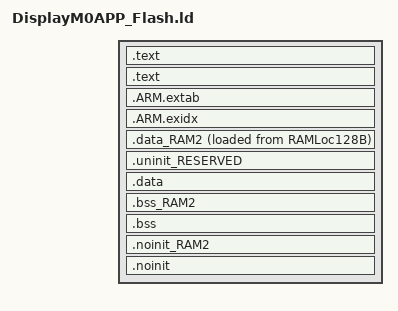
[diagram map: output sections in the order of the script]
/*
 * Modified for placing code on flash.
 * GENERATED FILE - DO NOT EDIT
 * (c) Code Red Technologies Ltd, 2008-13
 * (c) NXP Semiconductors 2013-2016
 * Generated linker script file for LPC4370-M0
 * Created from generic_c.ld (LPCXpresso v7.4 (0 [Build 229] [2014-09-16] ))
 * By LPCXpresso v7.4.0 [Build 229] [2014-09-16]  on Fri Jul 15 09:19:43 JST 2016
 */


INCLUDE "DisplayM0APP_Debug_lib.ld"
INCLUDE "DisplayM0APP_Debug_mem.ld"

ENTRY(ResetISR)

SECTIONS
{

    /* MAIN TEXT SECTION */    
    .text : ALIGN(4)
    {
        FILL(0xff)
        __vectors_start__ = ABSOLUTE(.) ;
        KEEP(*(.isr_vector))
        
        /* Global Section Table */
        . = ALIGN(4) ;
        __section_table_start = .;
        __data_section_table = .;
        LONG(LOADADDR(.data));
        LONG(    ADDR(.data));
        LONG(  SIZEOF(.data));
        LONG(LOADADDR(.data_RAM2));
        LONG(    ADDR(.data_RAM2));
        LONG(  SIZEOF(.data_RAM2));
        __data_section_table_end = .;
        __bss_section_table = .;
        LONG(    ADDR(.bss));
        LONG(  SIZEOF(.bss));
        LONG(    ADDR(.bss_RAM2));
        LONG(  SIZEOF(.bss_RAM2));
        __bss_section_table_end = .;
        __section_table_end = . ;
        /* End of Global Section Table */

        *(.after_vectors*)
        
    } >RAMLoc128B
    
    .text : ALIGN(4)    
    {
         *(.text*)
        *(.rodata .rodata.* .constdata .constdata.*)
        . = ALIGN(4);
        
    } > RAMLoc128B

    /*
     * for exception handling/unwind - some Newlib functions (in common
     * with C++ and STDC++) use this. 
     */
    .ARM.extab : ALIGN(4)
    {
    	*(.ARM.extab* .gnu.linkonce.armextab.*)
    } > RAMLoc128B
    __exidx_start = .;
    
    .ARM.exidx : ALIGN(4)
    {
    	*(.ARM.exidx* .gnu.linkonce.armexidx.*)
    } > RAMLoc128B
    __exidx_end = .;
    
    _etext = .;
        
    
    /* DATA section for RamLoc72 */
    .data_RAM2 : ALIGN(4)
    {
       FILL(0xff)
       *(.ramfunc.$RAM2)
       *(.ramfunc.$RamLoc72)
    	*(.data.$RAM2*)
    	*(.data.$RamLoc72*)
       . = ALIGN(4) ;
    } > RamLoc72 AT>RAMLoc128B
    
    /* MAIN DATA SECTION */
    

    .uninit_RESERVED : ALIGN(4)
    {
        KEEP(*(.bss.$RESERVED*))
        . = ALIGN(4) ;
        _end_uninit_RESERVED = .;
    } > RAMLoc128B

	
	/* Main DATA section (RAMLoc128B) */
	.data : ALIGN(4)
	{
	   FILL(0xff)
	   _data = . ;
	   *(vtable)
	   *(.ramfunc*)
	   *(.data*)
	   . = ALIGN(4) ;
	   _edata = . ;
	} > RAMLoc128B AT>RAMLoc128B

    /* BSS section for RamLoc72 */
    .bss_RAM2 : ALIGN(4)
    {
    	*(.bss.$RAM2*)
    	*(.bss.$RamLoc72*)
       . = ALIGN(4) ;
    } > RamLoc72

    /* MAIN BSS SECTION */
    .bss : ALIGN(4)
    {
        _bss = .;
        *(.bss*)
        *(COMMON)
        . = ALIGN(4) ;
        _ebss = .;
        PROVIDE(end = .);
    } > RAMLoc128B
        
    /* NOINIT section for RamLoc72 */
    .noinit_RAM2 (NOLOAD) : ALIGN(4)
    {
    	*(.noinit.$RAM2*)
    	*(.noinit.$RamLoc72*)
       . = ALIGN(4) ;
    } > RamLoc72 
    
    /* DEFAULT NOINIT SECTION */
    .noinit (NOLOAD): ALIGN(4)
    {
        _noinit = .;
        *(.noinit*) 
         . = ALIGN(4) ;
        _end_noinit = .;
    } > RAMLoc128B
    
    PROVIDE(_pvHeapStart = DEFINED(__user_heap_base) ? __user_heap_base : .);
    PROVIDE(_vStackTop = DEFINED(__user_stack_top) ? __user_stack_top : __top_RAMLoc128B - 0);
}
